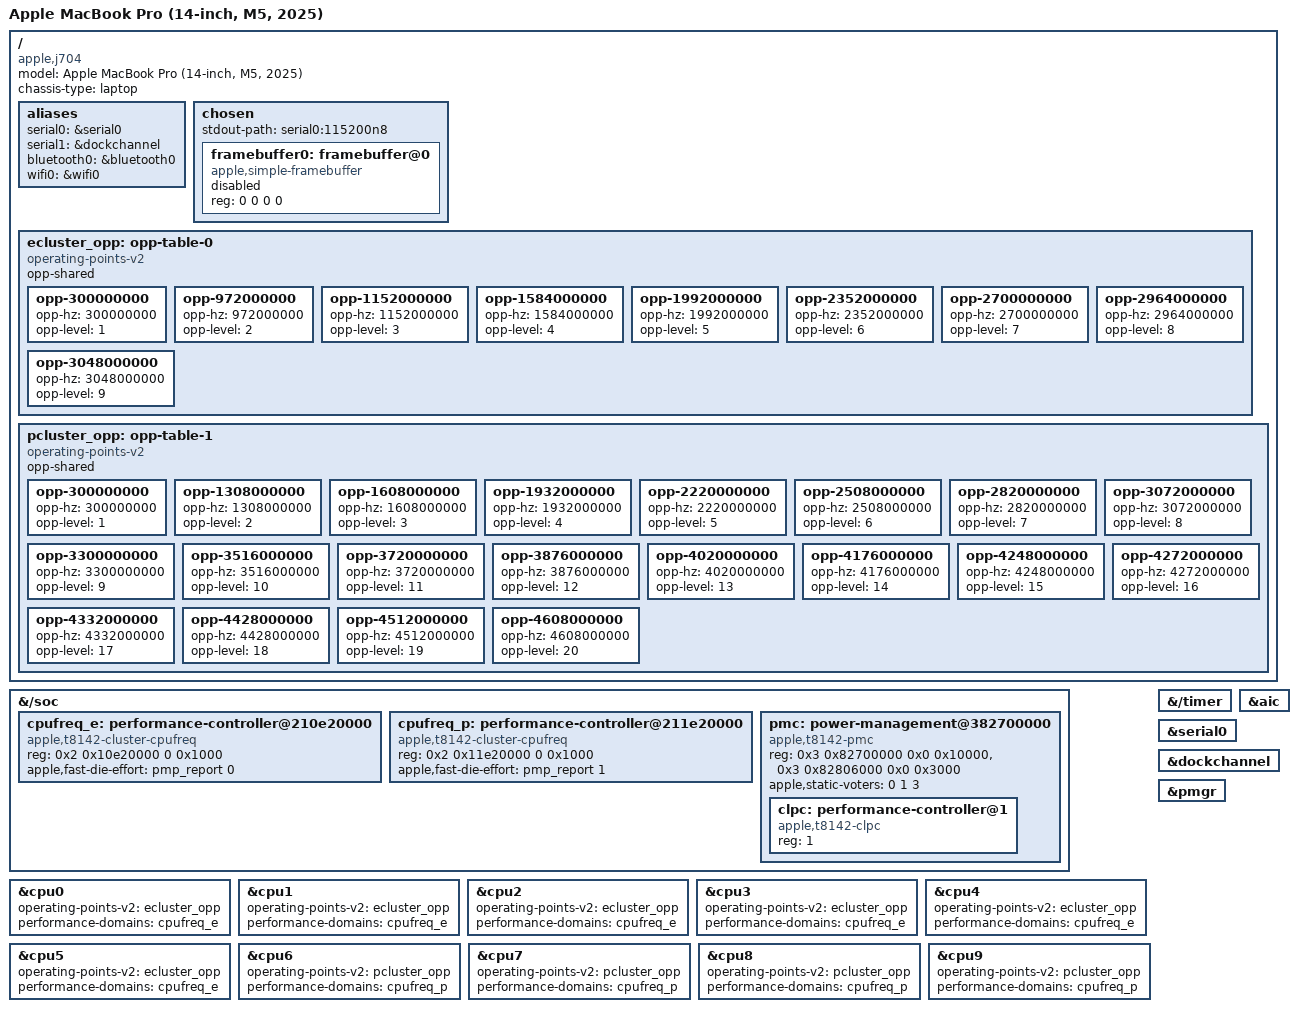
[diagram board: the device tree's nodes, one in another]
// SPDX-License-Identifier: GPL-2.0+ OR MIT
/*
 * Apple MacBook Pro (14-inch, M5, 2025), J704.
 *
 * Resources from the J704 Apple Device Tree. The loader supplies usable
 * memory, CPU release addresses and framebuffer geometry.
 */
/dts-v1/;

#include "t8142.dtsi"

/ {
	compatible = "apple,j704", "apple,t8142", "apple,arm-platform";
	model = "Apple MacBook Pro (14-inch, M5, 2025)";
	chassis-type = "laptop";

	aliases {
		serial0 = &serial0;
		serial1 = &dockchannel;
		bluetooth0 = &bluetooth0;
		wifi0 = &wifi0;
	};

	chosen {
		#address-cells = <2>;
		#size-cells = <2>;
		ranges;

		stdout-path = "serial0:115200n8";

		framebuffer0: framebuffer@0 {
			compatible = "apple,simple-framebuffer", "simple-framebuffer";
			reg = <0 0 0 0>; /* Filled by the loader. */
			status = "disabled";
		};
	};

	/*
	 * State 1 is 300 MHz; the ADT voltage-states1-sram (E) and
	 * voltage-states5-sram (P) tables begin at state 2.
	 */
	ecluster_opp: opp-table-0 {
		compatible = "operating-points-v2";
		opp-shared;

		opp-300000000 {
			opp-hz = /bits/ 64 <300000000>;
			opp-level = <1>;
		};

		opp-972000000 {
			opp-hz = /bits/ 64 <972000000>;
			opp-level = <2>;
		};

		opp-1152000000 {
			opp-hz = /bits/ 64 <1152000000>;
			opp-level = <3>;
		};

		opp-1584000000 {
			opp-hz = /bits/ 64 <1584000000>;
			opp-level = <4>;
		};

		opp-1992000000 {
			opp-hz = /bits/ 64 <1992000000>;
			opp-level = <5>;
		};

		opp-2352000000 {
			opp-hz = /bits/ 64 <2352000000>;
			opp-level = <6>;
		};

		opp-2700000000 {
			opp-hz = /bits/ 64 <2700000000>;
			opp-level = <7>;
		};

		opp-2964000000 {
			opp-hz = /bits/ 64 <2964000000>;
			opp-level = <8>;
		};

		opp-3048000000 {
			opp-hz = /bits/ 64 <3048000000>;
			opp-level = <9>;
		};
	};

	pcluster_opp: opp-table-1 {
		compatible = "operating-points-v2";
		opp-shared;

		opp-300000000 {
			opp-hz = /bits/ 64 <300000000>;
			opp-level = <1>;
		};

		opp-1308000000 {
			opp-hz = /bits/ 64 <1308000000>;
			opp-level = <2>;
		};

		opp-1608000000 {
			opp-hz = /bits/ 64 <1608000000>;
			opp-level = <3>;
		};

		opp-1932000000 {
			opp-hz = /bits/ 64 <1932000000>;
			opp-level = <4>;
		};

		opp-2220000000 {
			opp-hz = /bits/ 64 <2220000000>;
			opp-level = <5>;
		};

		opp-2508000000 {
			opp-hz = /bits/ 64 <2508000000>;
			opp-level = <6>;
		};

		opp-2820000000 {
			opp-hz = /bits/ 64 <2820000000>;
			opp-level = <7>;
		};

		opp-3072000000 {
			opp-hz = /bits/ 64 <3072000000>;
			opp-level = <8>;
		};

		opp-3300000000 {
			opp-hz = /bits/ 64 <3300000000>;
			opp-level = <9>;
		};

		opp-3516000000 {
			opp-hz = /bits/ 64 <3516000000>;
			opp-level = <10>;
		};

		/* The SoC throttles levels 11 and up when hot. */
		opp-3720000000 {
			opp-hz = /bits/ 64 <3720000000>;
			opp-level = <11>;
		};

		opp-3876000000 {
			opp-hz = /bits/ 64 <3876000000>;
			opp-level = <12>;
		};

		opp-4020000000 {
			opp-hz = /bits/ 64 <4020000000>;
			opp-level = <13>;
		};

		opp-4176000000 {
			opp-hz = /bits/ 64 <4176000000>;
			opp-level = <14>;
		};

		opp-4248000000 {
			opp-hz = /bits/ 64 <4248000000>;
			opp-level = <15>;
		};

		opp-4272000000 {
			opp-hz = /bits/ 64 <4272000000>;
			opp-level = <16>;
		};

		opp-4332000000 {
			opp-hz = /bits/ 64 <4332000000>;
			opp-level = <17>;
		};

		opp-4428000000 {
			opp-hz = /bits/ 64 <4428000000>;
			opp-level = <18>;
		};

		opp-4512000000 {
			opp-hz = /bits/ 64 <4512000000>;
			opp-level = <19>;
		};

		opp-4608000000 {
			opp-hz = /bits/ 64 <4608000000>;
			opp-level = <20>;
		};
	};
};

&{/soc} {
	cpufreq_e: performance-controller@210e20000 {
		compatible = "apple,t8142-cluster-cpufreq";
		reg = <0x2 0x10e20000 0 0x1000>;
		#performance-domain-cells = <0>;
		/* E lane follows the ADT ordering; no changing sample yet. */
		apple,fast-die-effort = <&pmp_report 0>;
	};

	cpufreq_p: performance-controller@211e20000 {
		compatible = "apple,t8142-cluster-cpufreq";
		reg = <0x2 0x11e20000 0 0x1000>;
		#performance-domain-cells = <0>;
		/* P lane has been observed under Linux CPU load. */
		apple,fast-die-effort = <&pmp_report 1>;
	};

	/*
	 * PMC voter interface (AppleT8142PMC, ADT pmc-pmgr 31 + 0x700000):
	 * floors at 0x382700000 + agent * 0x4000, per-agent states at
	 * +0x106000, rail enables at +0x108000. Agents (ADT voter-agent):
	 * PMP 0, CLPC 1, GFX 2, AP 3. iBoot leaves every enable at 0, so
	 * no vote is honoured and DRAM and fabric stay at their lowest
	 * states (CPU DRAM latency 171 ns instead of 70 ns).
	 */
	pmc: power-management@382700000 {
		compatible = "apple,t8142-pmc";
		reg = <0x3 0x82700000 0x0 0x10000>,
		      <0x3 0x82806000 0x0 0x3000>;
		reg-names = "voters", "rails";
		#address-cells = <1>;
		#size-cells = <0>;
		/* PMP, CLPC and AP agents */
		apple,static-voters = <0 1 3>;

		clpc: performance-controller@1 {
			compatible = "apple,t8142-clpc";
			reg = <1>;
		};
	};
};

&cpu0 {
	operating-points-v2 = <&ecluster_opp>;
	performance-domains = <&cpufreq_e>;
	status = "okay";
};

&cpu1 {
	operating-points-v2 = <&ecluster_opp>;
	performance-domains = <&cpufreq_e>;
	status = "okay";
};

&cpu2 {
	operating-points-v2 = <&ecluster_opp>;
	performance-domains = <&cpufreq_e>;
	status = "okay";
};

&cpu3 {
	operating-points-v2 = <&ecluster_opp>;
	performance-domains = <&cpufreq_e>;
	status = "okay";
};

&cpu4 {
	operating-points-v2 = <&ecluster_opp>;
	performance-domains = <&cpufreq_e>;
	status = "okay";
};

&cpu5 {
	operating-points-v2 = <&ecluster_opp>;
	performance-domains = <&cpufreq_e>;
	status = "okay";
};

&cpu6 {
	operating-points-v2 = <&pcluster_opp>;
	performance-domains = <&cpufreq_p>;
	status = "okay";
};

&cpu7 {
	operating-points-v2 = <&pcluster_opp>;
	performance-domains = <&cpufreq_p>;
	status = "okay";
};

&cpu8 {
	operating-points-v2 = <&pcluster_opp>;
	performance-domains = <&cpufreq_p>;
	status = "okay";
};

&cpu9 {
	operating-points-v2 = <&pcluster_opp>;
	performance-domains = <&cpufreq_p>;
	status = "okay";
};

&{/timer} {
	status = "okay";
};

&aic {
	status = "okay";
};

&serial0 {
	status = "okay";
};

&dockchannel {
	status = "okay";
};

&pmgr {
	status = "okay";
};

#include "t8142-j704-display.dtsi"
#include "t8142-j704-peripherals.dtsi"
#include "t8142-j704-usb.dtsi"
#include "t8142-j704-avd.dtsi"
#include "t8142-j704-nvme.dtsi"
#include "t8142-j704-pcie.dtsi"
#include "t8142-j704-power.dtsi"
#include "t8142-j704-hwmon.dtsi"
